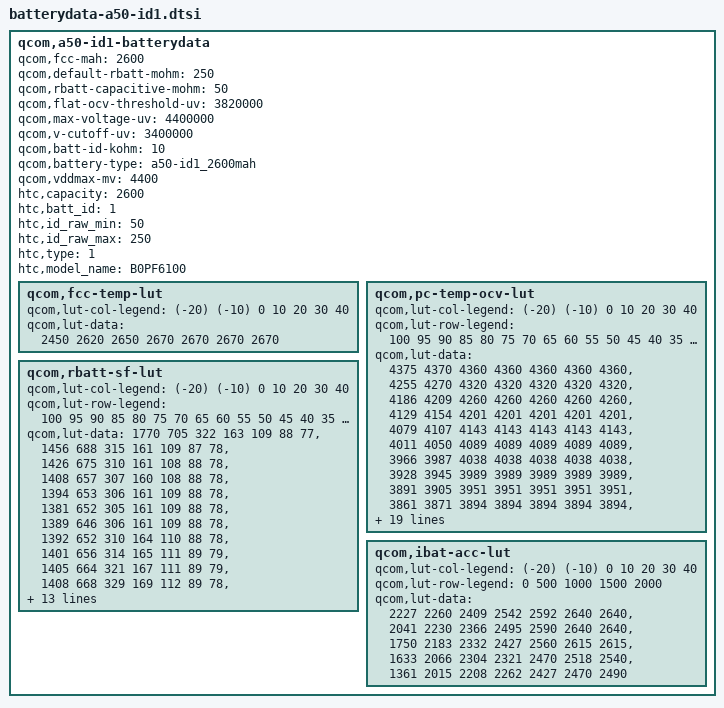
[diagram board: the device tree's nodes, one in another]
/* Copyright (c) 2013, The Linux Foundation. All rights reserved.
 *
 * This program is free software; you can redistribute it and/or modify
 * it under the terms of the GNU General Public License version 2 and
 * only version 2 as published by the Free Software Foundation.
 *
 * This program is distributed in the hope that it will be useful,
 * but WITHOUT ANY WARRANTY; without even the implied warranty of
 * MERCHANTABILITY or FITNESS FOR A PARTICULAR PURPOSE.  See the
 * GNU General Public License for more details.
 */

qcom,a50-id1-batterydata {
	qcom,fcc-mah = <2600>;
	qcom,default-rbatt-mohm = <250>;
	qcom,rbatt-capacitive-mohm = <50>;
	qcom,flat-ocv-threshold-uv = <3820000>;
	qcom,max-voltage-uv = <4400000>;
	qcom,v-cutoff-uv = <3400000>;
	qcom,batt-id-kohm = <10>;
	qcom,battery-type = "a50-id1_2600mah";
	qcom,vddmax-mv = <4400>;
	htc,capacity = <2600>;
	htc,batt_id = <1>;
	htc,id_raw_min = <50>;
	htc,id_raw_max = <250>;
	htc,type = <1>;
	htc,model_name = "B0PF6100";

	qcom,fcc-temp-lut {
		qcom,lut-col-legend = <(-20) (-10) 0 10 20 30 40>;
		qcom,lut-data = <2450 2620 2650 2670 2670 2670 2670>;
	};

	qcom,pc-temp-ocv-lut {
		qcom,lut-col-legend = <(-20) (-10) 0 10 20 30 40>;
		qcom,lut-row-legend = <100 95 90 85 80 75 70 65 60 55 50 45 40 35 30 25 20 15 10 9 8 7 6 5 4 3 2 1 0>;
		qcom,lut-data = <4375 4370 4360 4360 4360 4360 4360>,
				            <4255 4270 4320 4320 4320 4320 4320>,
				            <4186 4209 4260 4260 4260 4260 4260>,
				            <4129 4154 4201 4201 4201 4201 4201>,
				            <4079 4107 4143 4143 4143 4143 4143>,
				            <4011 4050 4089 4089 4089 4089 4089>,
				            <3966 3987 4038 4038 4038 4038 4038>,
				            <3928 3945 3989 3989 3989 3989 3989>,
				            <3891 3905 3951 3951 3951 3951 3951>,
				            <3861 3871 3894 3894 3894 3894 3894>,
				            <3838 3845 3855 3855 3855 3855 3855>,
				            <3822 3824 3830 3830 3830 3830 3830>,
				            <3809 3809 3809 3809 3809 3809 3809>,
				            <3794 3796 3793 3793 3793 3793 3793>,
				            <3779 3781 3780 3780 3780 3780 3780>,
				            <3762 3762 3759 3759 3759 3759 3759>,
				            <3745 3736 3739 3739 3739 3739 3739>,
				            <3723 3709 3712 3712 3712 3712 3712>,
				            <3692 3687 3685 3685 3685 3685 3685>,
				            <3681 3678 3683 3683 3683 3683 3683>,
				            <3670 3670 3680 3680 3680 3680 3680>,
				            <3659 3648 3675 3675 3675 3675 3675>,
				            <3648 3626 3670 3670 3670 3670 3670>,
				            <3638 3590 3641 3641 3641 3641 3641>,
				            <3619 3555 3613 3613 3613 3613 3613>,
				            <3600 3504 3544 3544 3544 3544 3544>,
				            <3581 3453 3476 3476 3476 3476 3476>,
				            <3562 3382 3282 3282 3282 3282 3282>,
				            <3544 3310 3088 3088 3088 3088 3088>;
	};

	qcom,rbatt-sf-lut {
		qcom,lut-col-legend = <(-20) (-10) 0 10 20 30 40>;
		qcom,lut-row-legend = <100 95 90 85 80 75 70 65 60 55 50 45 40 35 30 25 20 15 10 8 6 4 2 0>;
		qcom,lut-data = <1770 705 322 163 109 88 77>,
						<1456 688 315 161 109 87 78>,
						<1426 675 310 161 108 88 78>,
						<1408 657 307 160 108 88 78>,
						<1394 653 306 161 109 88 78>,
						<1381 652 305 161 109 88 78>,
						<1389 646 306 161 109 88 78>,
						<1392 652 310 164 110 88 78>,
						<1401 656 314 165 111 89 79>,
						<1405 664 321 167 111 89 79>,
						<1408 668 329 169 112 89 78>,
						<1406 678 343 173 113 90 79>,
						<1415 687 359 178 115 90 79>,
						<1438 697 379 185 117 91 80>,
						<1438 702 399 194 120 92 80>,
						<1438 718 417 202 124 94 81>,
						<1438 737 441 212 128 96 81>,
						<1438 750 474 223 132 98 83>,
						<1438 739 471 240 138 100 83>,
						<1438 748 479 245 194 100 86>,
						<1438 765 489 265 207 100 87>,
						<1440 786 503 293 217 105 95>,
						<1446 801 513 348 234 112 144>,
						<1463 834 544 431 262 157 176>;
	};

	qcom,ibat-acc-lut {
		qcom,lut-col-legend = <(-20) (-10) 0 10 20 30 40>;
		qcom,lut-row-legend = <0 500 1000 1500 2000>;
			qcom,lut-data = <2227 2260 2409 2542 2592 2640 2640>,
							<2041 2230 2366 2495 2590 2640 2640>,
							<1750 2183 2332 2427 2560 2615 2615>,
							<1633 2066 2304 2321 2470 2518 2540>,
							<1361 2015 2208 2262 2427 2470 2490>;
	};
};
